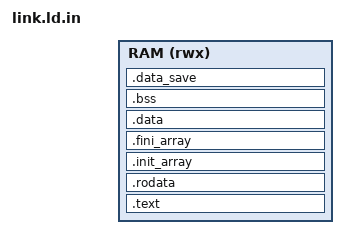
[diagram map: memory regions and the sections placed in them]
/* Ф0 bench: program, data, zone heap and stack in one region (@REGION@, made by the Makefile).
   SRAM 4 MB at 0 (frame buffer at 0x3f0000, resume area at 0x3ff000), SDRAM 32 MB at 0x10000000
   (program region 12 MB, the WAD at 0x10c00000, up to 20 MB), MMIO at 0x80000000. */
OUTPUT_ARCH("riscv")
ENTRY(_start)

MEMORY { RAM (rwx) : ORIGIN = @ORG@, LENGTH = @LEN@ }

STACK_SIZE = 64K;

SECTIONS
{
    .text : {
        KEEP(*(.text.start))
        *(.text .text.*)
    } > RAM
    .rodata : ALIGN(8) {
        *(.rodata .rodata.*)
        *(.srodata .srodata.*)
    } > RAM
    .init_array : { PROVIDE_HIDDEN(__init_array_start = .); KEEP(*(SORT(.init_array.*))) KEEP(*(.init_array)) PROVIDE_HIDDEN(__init_array_end = .); } > RAM
    .fini_array : { PROVIDE_HIDDEN(__fini_array_start = .); KEEP(*(SORT(.fini_array.*))) KEEP(*(.fini_array)) PROVIDE_HIDDEN(__fini_array_end = .); } > RAM
    .data : ALIGN(8) {
        __data_start = .;
        *(.data .data.*)
        __global_pointer$ = . + 0x800;
        *(.sdata .sdata.*)
        . = ALIGN(8);
        __data_end = .;
    } > RAM
    .bss (NOLOAD) : ALIGN(8) {
        __bss_start = .;
        *(.sbss .sbss.*)
        *(.bss .bss.*)
        *(COMMON)
        . = ALIGN(8);
        __bss_end = .;
    } > RAM
    /* the copy of .data as loaded (crt0_hw.S: a restart restores it) */
    .data_save (NOLOAD) : ALIGN(8) {
        __data_save = .;
        . += __data_end - __data_start;
    } > RAM
    __heap_start = .;
    __stack_top = ORIGIN(RAM) + LENGTH(RAM);
    __heap_end = __stack_top - STACK_SIZE;
}
